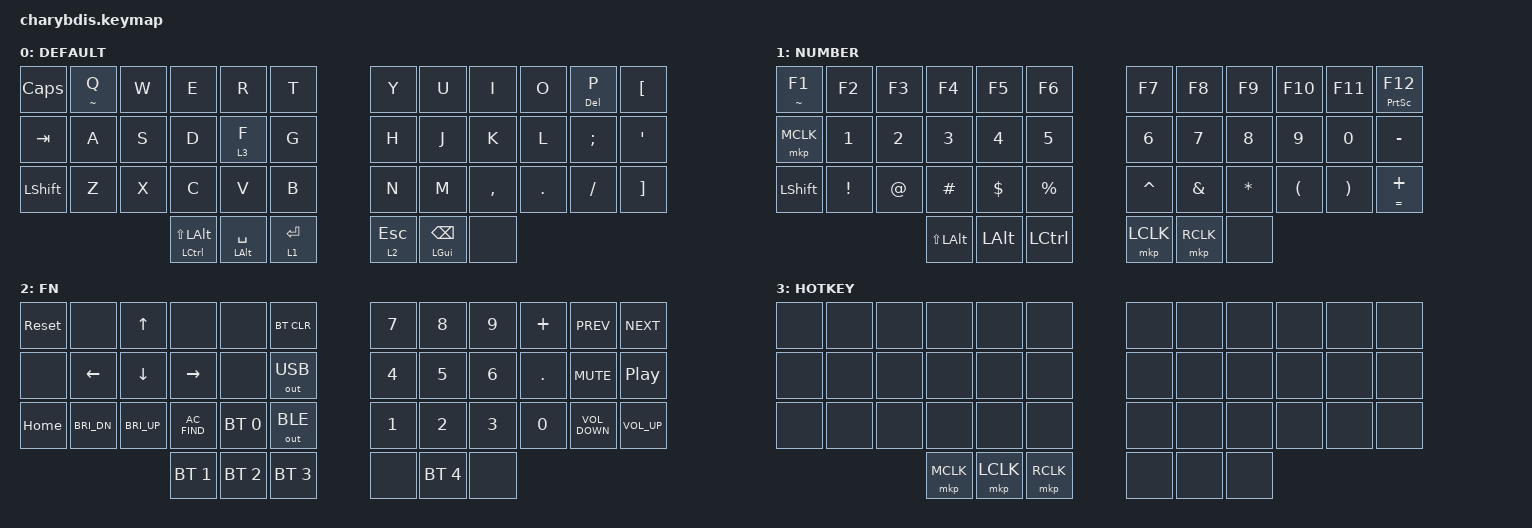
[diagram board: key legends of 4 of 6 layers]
#include <behaviors.dtsi>
#include <dt-bindings/zmk/keys.h>
#include <dt-bindings/zmk/bt.h>
#include <dt-bindings/zmk/ext_power.h>
#include <dt-bindings/zmk/mouse.h>
#include <dt-bindings/zmk/outputs.h>
#include <input/processors.dtsi>
#include <dt-bindings/zmk/input_transform.h>

#define U_TAPPING_TERM 200

/ {
    trackball_listener {
        compatible = "zmk,input-listener";
        device = <&trackball>;
        input-processors = <&zip_xy_scaler 1 2>, <&zip_temp_layer 4 400>; // Switch to auto-mouse temp layer, decrease sensitivity
        scroll {
            layers = <5>; // SCROLL
            input-processors = <&zip_xy_scaler 1 5>, <&zip_xy_to_scroll_mapper>, <&zip_scroll_transform (INPUT_TRANSFORM_Y_INVERT)>;
        };
    };

    combos {
        compatible = "zmk,combos";

        LeftClickRight {
            bindings = <&mkp LCLK>;
            key-positions = <19 20>;
        };

        RightClickRight {
            bindings = <&mkp RCLK>;
            key-positions = <20 21>;
        };

        MiddleClickRight {
            bindings = <&mkp MCLK>;
            key-positions = <21 22>;
        };

        ParaLeft {
            bindings = <&kp LEFT_PARENTHESIS>;
            key-positions = <4 16>;
        };

        ParaRight {
            bindings = <&kp RIGHT_PARENTHESIS>;
            key-positions = <7 19>;
        };

        BrakLeft {
            bindings = <&kp LEFT_BRACKET>;
            key-positions = <3 15>;
        };

        BrakRight {
            bindings = <&kp RIGHT_BRACKET>;
            key-positions = <8 20>;
        };

        BraceLeft {
            bindings = <&kp LEFT_BRACE>;
            key-positions = <2 14>;
        };

        BraceRight {
            bindings = <&kp RIGHT_BRACE>;
            key-positions = <9 21>;
        };

        Delete {
            bindings = <&kp DELETE>;
            key-positions = <8 9>;
        };

        CapsWord {
            bindings = <&caps_word>;
            key-positions = <17 18>;
        };
    };

    behaviors {
        u_mt: u_mt {
            compatible = "zmk,behavior-hold-tap";
            label = "u_mt";
            #binding-cells = <2>;
            tapping_term_ms = <U_TAPPING_TERM>;
            flavor = "tap-preferred";
            bindings = <&kp>, <&kp>;
        };

        u_lt: u_lt {
            compatible = "zmk,behavior-hold-tap";
            label = "u_lt";
            #binding-cells = <2>;
            tapping_term_ms = <U_TAPPING_TERM>;
            flavor = "tap-preferred";
            bindings = <&mo>, <&kp>;
        };

        Shift_Enter: Shift_Enter {
            compatible = "zmk,behavior-hold-tap";
            label = "SHIFT_ENTER";
            bindings = <&kp>, <&kp>;

            #binding-cells = <2>;
            hold-trigger-key-positions = <40>;
            tapping-term-ms = <100>;
        };
    };

    keymap {
        compatible = "zmk,keymap";

        default_layer {
            label = "DEFAULT";
            bindings = <
&kp CAPSLOCK  &mt TILDE Q  &kp W  &kp E                   &kp R               &kp T        &kp Y      &kp U                   &kp I      &kp O    &mt DELETE P  &kp LEFT_BRACKET
&kp TAB       &kp A        &kp S  &kp D                   &lt 3 F             &kp G        &kp H      &kp J                   &kp K      &kp L    &kp SEMI      &kp SQT
&kp LSHFT     &kp Z        &kp X  &kp C                   &kp V               &kp B        &kp N      &kp M                   &kp COMMA  &kp DOT  &kp FSLH      &kp RIGHT_BRACKET
                                  &mt LCTRL LS(LEFT_ALT)  &mt LEFT_ALT SPACE  &lt 1 ENTER  &lt 2 ESC  &mt LEFT_GUI BACKSPACE  &none
            >;
        };

        number_layer {
            label = "NUMBER";
            bindings = <
&mt TILDE F1  &kp F2           &kp F3       &kp F4            &kp F5        &kp F6       &kp F7     &kp F8         &kp F9        &kp F10               &kp F11                &mt PRINTSCREEN F12
&mkp MCLK     &kp N1           &kp N2       &kp N3            &kp N4        &kp N5       &kp N6     &kp N7         &kp N8        &kp N9                &kp N0                 &kp MINUS
&kp LSHFT     &kp EXCLAMATION  &kp AT_SIGN  &kp HASH          &kp DOLLAR    &kp PERCENT  &kp CARET  &kp AMPERSAND  &kp ASTERISK  &kp LEFT_PARENTHESIS  &kp RIGHT_PARENTHESIS  &mt EQUAL PLUS
                                            &kp LS(LEFT_ALT)  &kp LEFT_ALT  &kp LCTRL    &mkp LCLK  &mkp RCLK      &none
            >;
        };

        fn_layer {
            label = "FN";
            bindings = <
&sys_reset  &none         &kp UP_ARROW    &none          &none         &bt BT_CLR    &kp NUMBER_7  &kp NUMBER_8  &kp NUMBER_9  &kp PLUS      &kp C_PREV         &kp C_NEXT
&none       &kp LEFT      &kp DOWN_ARROW  &kp RIGHT      &none         &out OUT_USB  &kp NUMBER_4  &kp NUMBER_5  &kp NUMBER_6  &kp PERIOD    &kp K_MUTE         &kp C_PP
&kp HOME    &kp C_BRI_DN  &kp C_BRI_UP    &kp C_AC_FIND  &bt BT_SEL 0  &out OUT_BLE  &kp NUMBER_1  &kp NUMBER_2  &kp NUMBER_3  &kp NUMBER_0  &kp C_VOLUME_DOWN  &kp C_VOLUME_UP
                                          &bt BT_SEL 1   &bt BT_SEL 2  &bt BT_SEL 3  &none         &bt BT_SEL 4  &none
            >;
        };

        hotkey_layer {
            label = "HOTKEY";
            bindings = <
&none  &none  &none  &none      &none      &none      &none  &none  &none  &none  &none  &none
&none  &none  &none  &none      &none      &none      &none  &none  &none  &none  &none  &none
&none  &none  &none  &none      &none      &none      &none  &none  &none  &none  &none  &none
                     &mkp MCLK  &mkp LCLK  &mkp RCLK  &none  &none  &none
            >;
        };

        AUTO-MOUSE {
            bindings = <
&trans          &trans  &trans  &trans     &trans     &trans     &trans  &trans  &trans  &trans  &trans  &trans
&kp LCTRL       &trans  &trans  &trans     &trans     &trans     &trans  &trans  &trans  &trans  &trans  &trans
&kp LEFT_SHIFT  &trans  &trans  &trans     &trans     &trans     &trans  &trans  &trans  &trans  &trans  &trans
                                &mkp MCLK  &mkp LCLK  &mkp RCLK  &trans  &trans
            >;
        };

        SCROLL {
            bindings = <
&trans          &trans  &trans  &trans     &trans     &trans     &trans  &trans  &trans  &trans  &trans  &trans
&kp LCTRL       &trans  &trans  &trans     &trans     &trans     &trans  &trans  &trans  &trans  &trans  &trans
&kp LEFT_SHIFT  &trans  &trans  &trans     &trans     &trans     &trans  &trans  &trans  &trans  &trans  &trans
                                &mkp MCLK  &mkp LCLK  &mkp RCLK  &trans  &trans
            >;
        };
    };
};
